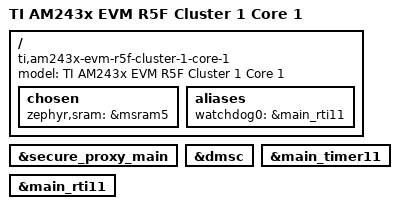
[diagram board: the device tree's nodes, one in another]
/* SPDX-FileCopyrightText: 2026 Texas Instruments Incorporated
 * SPDX-License-Identifier: Apache-2.0
 */
/dts-v1/;

#include <zephyr/dt-bindings/gpio/gpio.h>
#include <ti/am64x_r5f1_1.dtsi>

/ {
	model = "TI AM243x EVM R5F Cluster 1 Core 1";
	compatible = "ti,am243x-evm-r5f-cluster-1-core-1";

	chosen {
		zephyr,sram = &msram5;
	};

	aliases {
		watchdog0 = &main_rti11;
	};
};

&secure_proxy_main {
	status = "okay";
};

&dmsc {
	status = "okay";
};

/* system timer */
&main_timer11 {
	status = "okay";
};

&main_rti11 {
	status = "okay";
};
